# MDR1986BE4 register map
Registers are 32-bit, access not given, no defined reset value unless marked. A register's access mark holds for its fields unless they carry their own. Addresses are absolute; registers are grouped by the start of their names; [hi:lo] are bit positions; {n}, {i} and the like mark numbered series.

## TIMER1
0x40070000 TIMER1_CNT
  [15:0] CNT
0x40070004 TIMER1_PSG
  [15:0] PSG
0x40070008 TIMER1_ARR
  [15:0] ARR
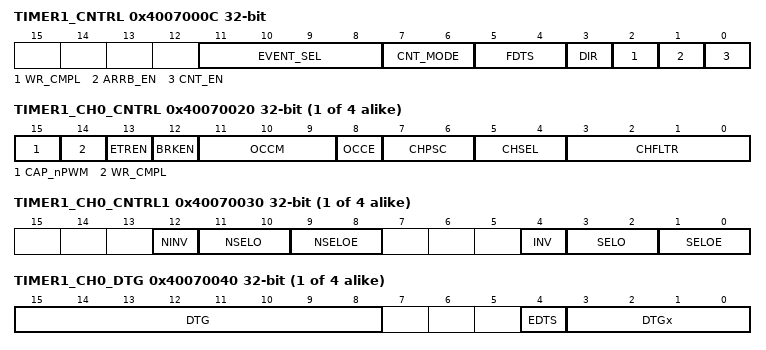
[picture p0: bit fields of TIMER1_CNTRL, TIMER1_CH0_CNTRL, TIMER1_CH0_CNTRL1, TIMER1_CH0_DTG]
0x4007000C TIMER1_CNTRL
  [11:8] EVENT_SEL, [7:6] CNT_MODE, [5:4] FDTS, [3] DIR, [2] WR_CMPL, [1] ARRB_EN, [0] CNT_EN
0x40070010 TIMER1_CCR0
  [15:0] CCR
0x40070014 TIMER1_CCR1
  [15:0] CCR
0x40070018 TIMER1_CCR2
  [15:0] CCR
0x4007001C TIMER1_CCR3
  [15:0] CCR
{0x40070020+4i} TIMER1_CH{i}_CNTRL (i=0..3)
  [15] CAP_nPWM, [14] WR_CMPL, [13] ETREN, [12] BRKEN, [11:9] OCCM, [8] OCCE, [7:6] CHPSC, [5:4] CHSEL, [3:0] CHFLTR
{0x40070030+4i} TIMER1_CH{i}_CNTRL1 (i=0..3)
  [12] NINV, [11:10] NSELO, [9:8] NSELOE, [4] INV, [3:2] SELO, [1:0] SELOE
{0x40070040+4i} TIMER1_CH{i}_DTG (i=0..3)
  [15:8] DTG, [4] EDTS, [3:0] DTGx
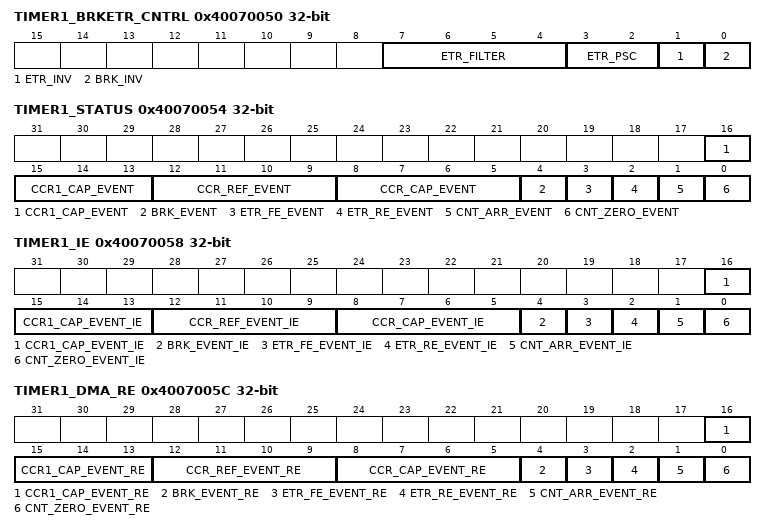
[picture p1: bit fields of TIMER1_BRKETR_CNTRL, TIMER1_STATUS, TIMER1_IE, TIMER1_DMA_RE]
0x40070050 TIMER1_BRKETR_CNTRL
  [7:4] ETR_FILTER, [3:2] ETR_PSC, [1] ETR_INV, [0] BRK_INV
0x40070054 TIMER1_STATUS
  [16:13] CCR1_CAP_EVENT, [12:9] CCR_REF_EVENT, [8:5] CCR_CAP_EVENT, [4] BRK_EVENT, [3] ETR_FE_EVENT, [2] ETR_RE_EVENT, [1] CNT_ARR_EVENT, [0] CNT_ZERO_EVENT
0x40070058 TIMER1_IE
  [16:13] CCR1_CAP_EVENT_IE, [12:9] CCR_REF_EVENT_IE, [8:5] CCR_CAP_EVENT_IE, [4] BRK_EVENT_IE, [3] ETR_FE_EVENT_IE, [2] ETR_RE_EVENT_IE, [1] CNT_ARR_EVENT_IE, [0] CNT_ZERO_EVENT_IE
0x4007005C TIMER1_DMA_RE
  [16:13] CCR1_CAP_EVENT_RE, [12:9] CCR_REF_EVENT_RE, [8:5] CCR_CAP_EVENT_RE, [4] BRK_EVENT_RE, [3] ETR_FE_EVENT_RE, [2] ETR_RE_EVENT_RE, [1] CNT_ARR_EVENT_RE, [0] CNT_ZERO_EVENT_RE
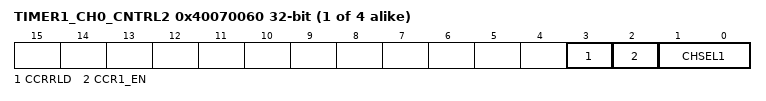
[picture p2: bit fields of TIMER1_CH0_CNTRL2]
{0x40070060+4i} TIMER1_CH{i}_CNTRL2 (i=0..3)
  [3] CCRRLD, [2] CCR1_EN, [1:0] CHSEL1
0x40070070 TIMER1_CCR01
  [15:0] CCR
0x40070074 TIMER1_CCR11
  [15:0] CCR
0x40070078 TIMER1_CCR21
  [15:0] CCR
0x4007007C TIMER1_CCR31
  [15:0] CCR

## TIMER2
0x40078000 TIMER2_CNT
  [15:0] CNT
0x40078004 TIMER2_PSG
  [15:0] PSG
0x40078008 TIMER2_ARR
  [15:0] ARR
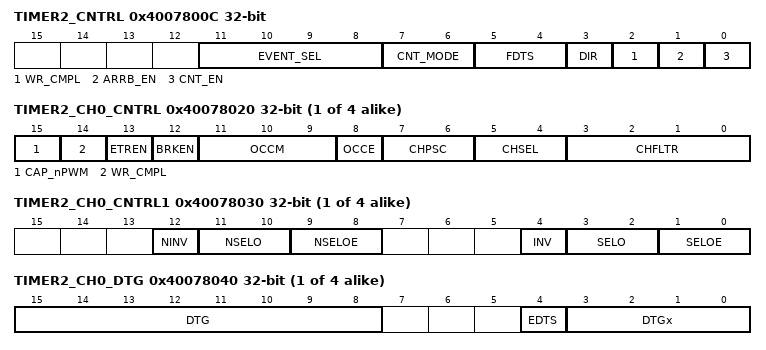
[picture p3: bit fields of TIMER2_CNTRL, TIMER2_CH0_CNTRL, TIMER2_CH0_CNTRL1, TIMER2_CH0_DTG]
0x4007800C TIMER2_CNTRL
  [11:8] EVENT_SEL, [7:6] CNT_MODE, [5:4] FDTS, [3] DIR, [2] WR_CMPL, [1] ARRB_EN, [0] CNT_EN
0x40078010 TIMER2_CCR0
  [15:0] CCR
0x40078014 TIMER2_CCR1
  [15:0] CCR
0x40078018 TIMER2_CCR2
  [15:0] CCR
0x4007801C TIMER2_CCR3
  [15:0] CCR
{0x40078020+4i} TIMER2_CH{i}_CNTRL (i=0..3)
  [15] CAP_nPWM, [14] WR_CMPL, [13] ETREN, [12] BRKEN, [11:9] OCCM, [8] OCCE, [7:6] CHPSC, [5:4] CHSEL, [3:0] CHFLTR
{0x40078030+4i} TIMER2_CH{i}_CNTRL1 (i=0..3)
  [12] NINV, [11:10] NSELO, [9:8] NSELOE, [4] INV, [3:2] SELO, [1:0] SELOE
{0x40078040+4i} TIMER2_CH{i}_DTG (i=0..3)
  [15:8] DTG, [4] EDTS, [3:0] DTGx
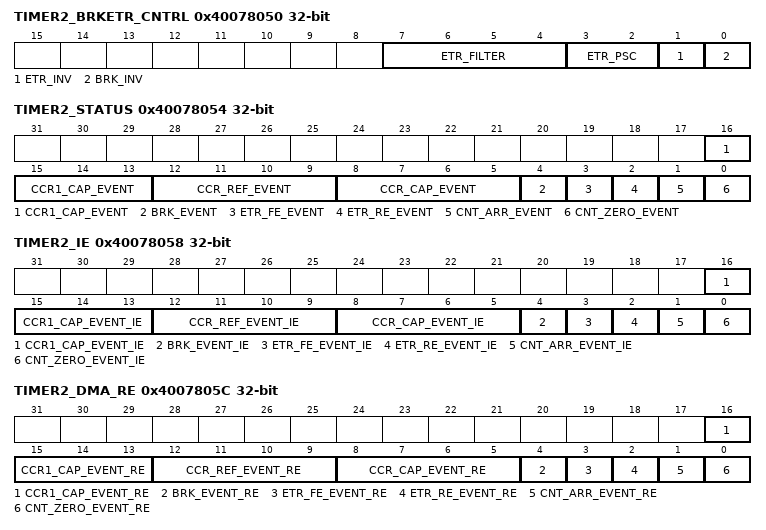
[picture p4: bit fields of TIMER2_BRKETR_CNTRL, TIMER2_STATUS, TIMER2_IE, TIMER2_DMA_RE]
0x40078050 TIMER2_BRKETR_CNTRL
  [7:4] ETR_FILTER, [3:2] ETR_PSC, [1] ETR_INV, [0] BRK_INV
0x40078054 TIMER2_STATUS
  [16:13] CCR1_CAP_EVENT, [12:9] CCR_REF_EVENT, [8:5] CCR_CAP_EVENT, [4] BRK_EVENT, [3] ETR_FE_EVENT, [2] ETR_RE_EVENT, [1] CNT_ARR_EVENT, [0] CNT_ZERO_EVENT
0x40078058 TIMER2_IE
  [16:13] CCR1_CAP_EVENT_IE, [12:9] CCR_REF_EVENT_IE, [8:5] CCR_CAP_EVENT_IE, [4] BRK_EVENT_IE, [3] ETR_FE_EVENT_IE, [2] ETR_RE_EVENT_IE, [1] CNT_ARR_EVENT_IE, [0] CNT_ZERO_EVENT_IE
0x4007805C TIMER2_DMA_RE
  [16:13] CCR1_CAP_EVENT_RE, [12:9] CCR_REF_EVENT_RE, [8:5] CCR_CAP_EVENT_RE, [4] BRK_EVENT_RE, [3] ETR_FE_EVENT_RE, [2] ETR_RE_EVENT_RE, [1] CNT_ARR_EVENT_RE, [0] CNT_ZERO_EVENT_RE
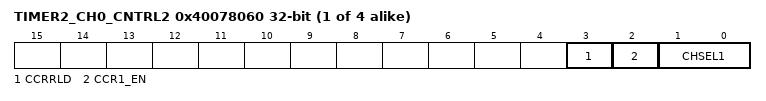
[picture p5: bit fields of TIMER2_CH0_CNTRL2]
{0x40078060+4i} TIMER2_CH{i}_CNTRL2 (i=0..3)
  [3] CCRRLD, [2] CCR1_EN, [1:0] CHSEL1
0x40078070 TIMER2_CCR01
  [15:0] CCR
0x40078074 TIMER2_CCR11
  [15:0] CCR
0x40078078 TIMER2_CCR21
  [15:0] CCR
0x4007807C TIMER2_CCR31
  [15:0] CCR

## PORTA
0x40080000 PORTA_RXTX
  [15:0] RXTX
0x40080004 PORTA_OE
  [15:0] OE
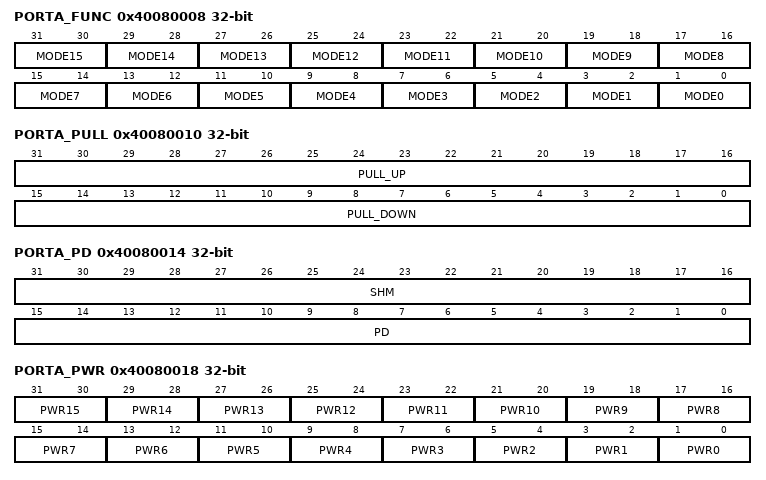
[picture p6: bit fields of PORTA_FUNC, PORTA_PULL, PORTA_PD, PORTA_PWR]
0x40080008 PORTA_FUNC
  [2n+1:2n] MODE{n} (n=0..15)
0x4008000C PORTA_ANALOG
  [15:0] ANALOG_EN
0x40080010 PORTA_PULL
  [31:16] PULL_UP, [15:0] PULL_DOWN
0x40080014 PORTA_PD
  [31:16] SHM, [15:0] PD
0x40080018 PORTA_PWR
  [2n+1:2n] PWR{n} (n=0..15)
0x4008001C PORTA_GFEN
  [15:0] GFEN

## PORTB
0x40088000 PORTB_RXTX
  [15:0] RXTX
0x40088004 PORTB_OE
  [15:0] OE
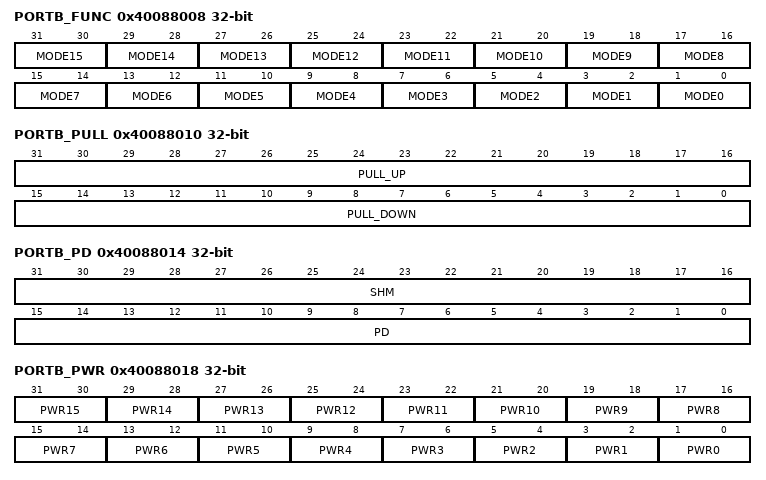
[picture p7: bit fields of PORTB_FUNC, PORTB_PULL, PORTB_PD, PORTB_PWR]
0x40088008 PORTB_FUNC
  [2n+1:2n] MODE{n} (n=0..15)
0x4008800C PORTB_ANALOG
  [15:0] ANALOG_EN
0x40088010 PORTB_PULL
  [31:16] PULL_UP, [15:0] PULL_DOWN
0x40088014 PORTB_PD
  [31:16] SHM, [15:0] PD
0x40088018 PORTB_PWR
  [2n+1:2n] PWR{n} (n=0..15)
0x4008801C PORTB_GFEN
  [15:0] GFEN

## PORTC
0x40090000 PORTC_RXTX
  [15:0] RXTX
0x40090004 PORTC_OE
  [15:0] OE
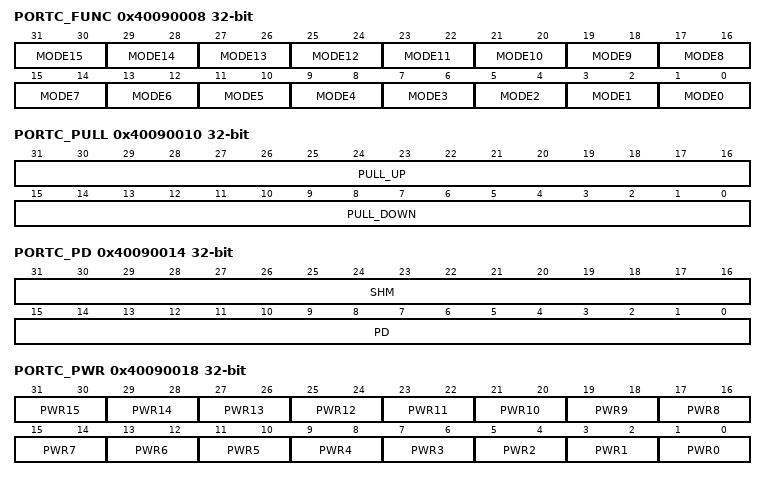
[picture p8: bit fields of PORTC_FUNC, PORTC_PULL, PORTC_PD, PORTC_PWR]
0x40090008 PORTC_FUNC
  [2n+1:2n] MODE{n} (n=0..15)
0x4009000C PORTC_ANALOG
  [15:0] ANALOG_EN
0x40090010 PORTC_PULL
  [31:16] PULL_UP, [15:0] PULL_DOWN
0x40090014 PORTC_PD
  [31:16] SHM, [15:0] PD
0x40090018 PORTC_PWR
  [2n+1:2n] PWR{n} (n=0..15)
0x4009001C PORTC_GFEN
  [15:0] GFEN

## SFR
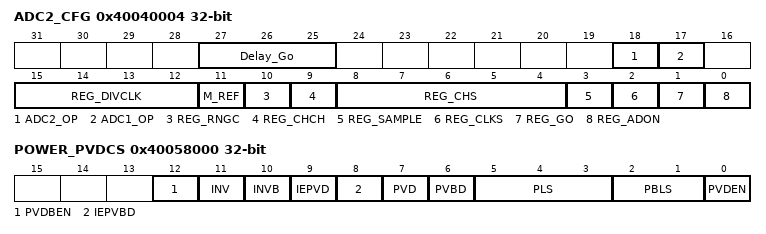
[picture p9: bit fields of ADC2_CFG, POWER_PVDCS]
0x40040004 ADC2_CFG
  [27:25] Delay_Go, [18] ADC2_OP, [17] ADC1_OP, [15:12] REG_DIVCLK, [11] M_REF, [10] REG_RNGC, [9] REG_CHCH, [8:4] REG_CHS, [3] REG_SAMPLE, [2] REG_CLKS, [1] REG_GO, [0] REG_ADON
0x40058000 POWER_PVDCS
  [12] PVDBEN, [11] INV, [10] INVB, [9] IEPVD, [8] IEPVBD, [7] PVD, [6] PVBD, [5:3] PLS, [2:1] PBLS, [0] PVDEN
